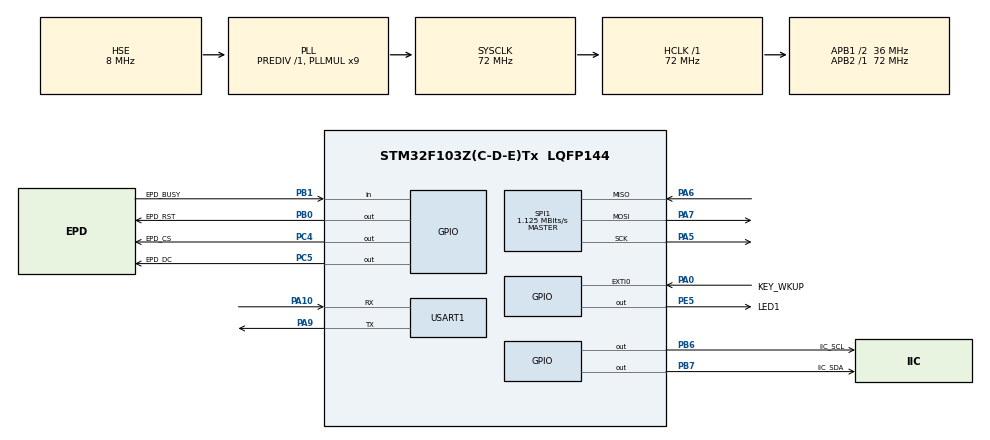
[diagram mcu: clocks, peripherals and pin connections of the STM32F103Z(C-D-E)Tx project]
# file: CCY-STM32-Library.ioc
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Mcu.Family=STM32F1
Mcu.Name=STM32F103Z(C-D-E)Tx
Mcu.Package=LQFP144
NVIC.EXTI0_IRQn=true\:0\:0\:false\:false\:true\:true\:true\:true
NVIC.PriorityGroup=NVIC_PRIORITYGROUP_4
NVIC.USART1_IRQn=true\:0\:0\:false\:false\:true\:true\:true\:true
OSC_IN.Mode=HSE-External-Oscillator
OSC_IN.Signal=RCC_OSC_IN
OSC_OUT.Mode=HSE-External-Oscillator
OSC_OUT.Signal=RCC_OSC_OUT
PA0-WKUP.GPIO_Label=KEY_WKUP
PA0-WKUP.GPIO_ModeDefaultEXTI=GPIO_MODE_IT_RISING
PA0-WKUP.GPIO_PuPd=GPIO_PULLDOWN
PA0-WKUP.Signal=GPXTI0
PA10.Mode=Asynchronous
PA10.Signal=USART1_RX
PA13.Mode=Serial_Wire
PA13.Signal=SYS_JTMS-SWDIO
PA14.Mode=Serial_Wire
PA14.Signal=SYS_JTCK-SWCLK
PA5.Mode=Full_Duplex_Master
PA5.Signal=SPI1_SCK
PA6.Mode=Full_Duplex_Master
PA6.Signal=SPI1_MISO
PA7.Mode=Full_Duplex_Master
PA7.Signal=SPI1_MOSI
PA9.Mode=Asynchronous
PA9.Signal=USART1_TX
PB0.GPIO_Label=EPD_RST
PB0.GPIO_ModeDefaultOutputPP=GPIO_MODE_OUTPUT_PP
PB0.Signal=GPIO_Output
PB1.GPIO_Label=EPD_BUSY
PB1.Signal=GPIO_Input
PB6.GPIO_Label=IIC_SCL
PB6.GPIO_ModeDefaultOutputPP=GPIO_MODE_OUTPUT_OD
PB6.GPIO_PuPd=GPIO_NOPULL
PB6.GPIO_Speed=GPIO_SPEED_FREQ_HIGH
PB6.PinState=GPIO_PIN_SET
PB6.Signal=GPIO_Output
PB7.GPIO_Label=IIC_SDA
PB7.GPIO_ModeDefaultOutputPP=GPIO_MODE_OUTPUT_OD
PB7.GPIO_PuPd=GPIO_NOPULL
PB7.GPIO_Speed=GPIO_SPEED_FREQ_HIGH
PB7.PinState=GPIO_PIN_SET
PB7.Signal=GPIO_Output
PC4.GPIO_Label=EPD_CS
PC4.Signal=GPIO_Output
PC5.GPIO_Label=EPD_DC
PC5.Signal=GPIO_Output
PE5.GPIO_Label=LED1
PE5.Signal=GPIO_Output
ProjectManager.HeapSize=0x200
ProjectManager.StackSize=0x400
ProjectManager.TargetToolchain=STM32CubeIDE
RCC.AHBFreq_Value=72000000
RCC.APB1CLKDivider=RCC_HCLK_DIV2
RCC.APB1Freq_Value=36000000
RCC.APB1TimFreq_Value=72000000
RCC.APB2Freq_Value=72000000
RCC.APB2TimFreq_Value=72000000
RCC.HCLKFreq_Value=72000000
RCC.PLLMUL=RCC_PLL_MUL9
RCC.PLLSourceVirtual=RCC_PLLSOURCE_HSE
RCC.SYSCLKFreq_VALUE=72000000
RCC.SYSCLKSource=RCC_SYSCLKSOURCE_PLLCLK
RCC.USBFreq_Value=72000000
SPI1.BaudRatePrescaler=SPI_BAUDRATEPRESCALER_64
SPI1.CalculateBaudRate=1.125 MBits/s
SPI1.Direction=SPI_DIRECTION_2LINES
SPI1.Mode=SPI_MODE_MASTER
SPI1.VirtualType=VM_MASTER
USART1.VirtualMode=VM_ASYNC
board=custom

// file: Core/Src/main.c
/* USER CODE BEGIN Header */
/**
  ******************************************************************************
  * @file           : main.c
  * @brief          : Main program body
  ******************************************************************************
  * @attention
  *
  * Copyright (c) 2023 STMicroelectronics.
  * All rights reserved.
  *
  * This software is licensed under terms that can be found in the LICENSE file
  * in the root directory of this software component.
  * If no LICENSE file comes with this software, it is provided AS-IS.
  *
  ******************************************************************************
  */
/* USER CODE END Header */
#include "main.h"
#include "spi.h"
#include "usart.h"
#include "gpio.h"

/* USER CODE BEGIN Includes */
//#include "at24c02.h"
#include "delay.h"
//#include "aht20.h"
//墨水屏驱动
#include "EPD_Test.h"
/* USER CODE END Includes */

void SystemClock_Config(void);

int main(void) {

    /* MCU Configuration--------------------------------------------------------*/

    /* Reset of all peripherals, Initializes the Flash interface and the Systick. */
    HAL_Init();

    /* Configure the system clock */
    SystemClock_Config();

    /* USER CODE BEGIN SysInit */
    delay_init(72);
    /* USER CODE END SysInit */

    /* Initialize all configured peripherals */
    MX_GPIO_Init();
    MX_USART1_UART_Init();
    MX_SPI1_Init();
    /* USER CODE BEGIN 2 */
    printf("Hello\n");
    delay_s(1);
    printf("Hello2\n");
//    C02_Init();
//    printf("State %d\n", C02_Write(100, 'C'));
//    aht20_init();

    EPD_test();
    /* USER CODE END 2 */

    /* Infinite loop */
    /* USER CODE BEGIN WHILE */
//    uint8_t dat;
//    float h, t;
    while (1) {
        delay_s(1);
        HAL_GPIO_TogglePin(LED1_GPIO_Port, LED1_Pin);
//        dat = C02_Read(100);
//        printf("打印EEPROM数据: %c \n", dat);
//        aht20_read(&h, &t);
//        printf("湿度:%.1f 温度:%.1f \n\n", h, t);
        /* USER CODE END WHILE */

    }
}

void SystemClock_Config(void) {
    RCC_OscInitTypeDef RCC_OscInitStruct = {0};
    RCC_ClkInitTypeDef RCC_ClkInitStruct = {0};

    /** Initializes the RCC Oscillators according to the specified parameters
    * in the RCC_OscInitTypeDef structure.
    */
    RCC_OscInitStruct.OscillatorType = RCC_OSCILLATORTYPE_HSE;
    RCC_OscInitStruct.HSEState = RCC_HSE_ON;
    RCC_OscInitStruct.HSEPredivValue = RCC_HSE_PREDIV_DIV1;
    RCC_OscInitStruct.HSIState = RCC_HSI_ON;
    RCC_OscInitStruct.PLL.PLLState = RCC_PLL_ON;
    RCC_OscInitStruct.PLL.PLLSource = RCC_PLLSOURCE_HSE;
    RCC_OscInitStruct.PLL.PLLMUL = RCC_PLL_MUL9;
    if (HAL_RCC_OscConfig(&RCC_OscInitStruct) != HAL_OK) {
        Error_Handler();
    }

    /** Initializes the CPU, AHB and APB buses clocks
    */
    RCC_ClkInitStruct.ClockType = RCC_CLOCKTYPE_HCLK | RCC_CLOCKTYPE_SYSCLK
                                  | RCC_CLOCKTYPE_PCLK1 | RCC_CLOCKTYPE_PCLK2;
    RCC_ClkInitStruct.SYSCLKSource = RCC_SYSCLKSOURCE_PLLCLK;
    RCC_ClkInitStruct.AHBCLKDivider = RCC_SYSCLK_DIV1;
    RCC_ClkInitStruct.APB1CLKDivider = RCC_HCLK_DIV2;
    RCC_ClkInitStruct.APB2CLKDivider = RCC_HCLK_DIV1;

    if (HAL_RCC_ClockConfig(&RCC_ClkInitStruct, FLASH_LATENCY_2) != HAL_OK) {
        Error_Handler();
    }
}

void Error_Handler(void) {
    /* USER CODE BEGIN Error_Handler_Debug */
    /* User can add his own implementation to report the HAL error return state */
    __disable_irq();
    while (1) {
        delay_s(1);
        printf("系统报错\n");
    }
    /* USER CODE END Error_Handler_Debug */
}
